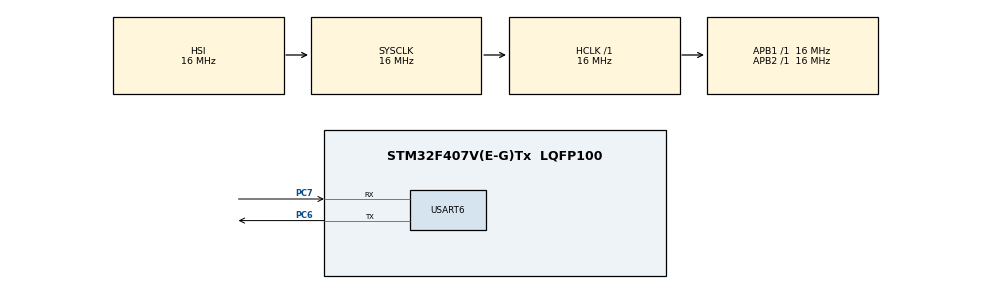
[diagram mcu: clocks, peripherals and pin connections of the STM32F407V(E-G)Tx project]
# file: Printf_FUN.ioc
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Mcu.Family=STM32F4
Mcu.Name=STM32F407V(E-G)Tx
Mcu.Package=LQFP100
NVIC.PriorityGroup=NVIC_PRIORITYGROUP_4
PA13.Mode=Serial_Wire
PA13.Signal=SYS_JTMS-SWDIO
PA14.Mode=Serial_Wire
PA14.Signal=SYS_JTCK-SWCLK
PC6.Mode=Asynchronous
PC6.Signal=USART6_TX
PC7.Mode=Asynchronous
PC7.Signal=USART6_RX
PH0-OSC_IN.Mode=HSE-External-Oscillator
PH0-OSC_IN.Signal=RCC_OSC_IN
PH1-OSC_OUT.Mode=HSE-External-Oscillator
PH1-OSC_OUT.Signal=RCC_OSC_OUT
ProjectManager.HeapSize=0x200
ProjectManager.StackSize=0x400
ProjectManager.TargetToolchain=STM32CubeIDE
RCC.AHBFreq_Value=16000000
RCC.APB1Freq_Value=16000000
RCC.APB2Freq_Value=16000000
RCC.CortexFreq_Value=16000000
RCC.HSE_VALUE=25000000
RCC.HSI_VALUE=16000000
RCC.LSE_VALUE=32768
RCC.SYSCLKFreq_VALUE=16000000
RCC.VCOOutputFreq_Value=192000000
USART6.VirtualMode=VM_ASYNC
board=custom

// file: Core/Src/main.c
/* USER CODE BEGIN Header */
/**
  ******************************************************************************
  * @file           : main.c
  * @brief          : Main program body
  ******************************************************************************
  * @attention
  *
  * Copyright (c) 2023 STMicroelectronics.
  * All rights reserved.
  *
  * This software is licensed under terms that can be found in the LICENSE file
  * in the root directory of this software component.
  * If no LICENSE file comes with this software, it is provided AS-IS.
  *
  ******************************************************************************
  */
/* USER CODE END Header */
#include "main.h"

/* USER CODE BEGIN Includes */
#include<stdio.h>

/* USER CODE END Includes */

UART_HandleTypeDef huart6;

void SystemClock_Config(void);
static void MX_GPIO_Init(void);
static void MX_USART6_UART_Init(void);
/* USER CODE BEGIN PFP */

#define PUTCHAR_PROTOTYPE int __io_putchar(int ch)

/* USER CODE END PFP */

int main(void)
{

  /* MCU Configuration--------------------------------------------------------*/

  /* Reset of all peripherals, Initializes the Flash interface and the Systick. */
  HAL_Init();

  /* Configure the system clock */
  SystemClock_Config();

  /* Initialize all configured peripherals */
  MX_GPIO_Init();
  MX_USART6_UART_Init();
  /* USER CODE BEGIN 2 */
  printf("Hello\n");
  /* USER CODE END 2 */

  /* Infinite loop */
  /* USER CODE BEGIN WHILE */
  while (1)
  {
	  printf("Hello\n");
	  HAL_Delay(1000);
    /* USER CODE END WHILE */

  }
}

void SystemClock_Config(void)
{
  RCC_OscInitTypeDef RCC_OscInitStruct = {0};
  RCC_ClkInitTypeDef RCC_ClkInitStruct = {0};

  /** Configure the main internal regulator output voltage
  */
  __HAL_RCC_PWR_CLK_ENABLE();
  __HAL_PWR_VOLTAGESCALING_CONFIG(PWR_REGULATOR_VOLTAGE_SCALE1);

  /** Initializes the RCC Oscillators according to the specified parameters
  * in the RCC_OscInitTypeDef structure.
  */
  RCC_OscInitStruct.OscillatorType = RCC_OSCILLATORTYPE_HSI;
  RCC_OscInitStruct.HSIState = RCC_HSI_ON;
  RCC_OscInitStruct.HSICalibrationValue = RCC_HSICALIBRATION_DEFAULT;
  RCC_OscInitStruct.PLL.PLLState = RCC_PLL_NONE;
  if (HAL_RCC_OscConfig(&RCC_OscInitStruct) != HAL_OK)
  {
    Error_Handler();
  }

  /** Initializes the CPU, AHB and APB buses clocks
  */
  RCC_ClkInitStruct.ClockType = RCC_CLOCKTYPE_HCLK|RCC_CLOCKTYPE_SYSCLK
                              |RCC_CLOCKTYPE_PCLK1|RCC_CLOCKTYPE_PCLK2;
  RCC_ClkInitStruct.SYSCLKSource = RCC_SYSCLKSOURCE_HSI;
  RCC_ClkInitStruct.AHBCLKDivider = RCC_SYSCLK_DIV1;
  RCC_ClkInitStruct.APB1CLKDivider = RCC_HCLK_DIV1;
  RCC_ClkInitStruct.APB2CLKDivider = RCC_HCLK_DIV1;

  if (HAL_RCC_ClockConfig(&RCC_ClkInitStruct, FLASH_LATENCY_0) != HAL_OK)
  {
    Error_Handler();
  }
}

static void MX_USART6_UART_Init(void)
{

  huart6.Instance = USART6;
  huart6.Init.BaudRate = 115200;
  huart6.Init.WordLength = UART_WORDLENGTH_8B;
  huart6.Init.StopBits = UART_STOPBITS_1;
  huart6.Init.Parity = UART_PARITY_NONE;
  huart6.Init.Mode = UART_MODE_TX_RX;
  huart6.Init.HwFlowCtl = UART_HWCONTROL_NONE;
  huart6.Init.OverSampling = UART_OVERSAMPLING_16;
  if (HAL_UART_Init(&huart6) != HAL_OK)
  {
    Error_Handler();
  }

}

static void MX_GPIO_Init(void)
{

  /* GPIO Ports Clock Enable */
  __HAL_RCC_GPIOH_CLK_ENABLE();
  __HAL_RCC_GPIOC_CLK_ENABLE();
  __HAL_RCC_GPIOA_CLK_ENABLE();

}

/* USER CODE BEGIN 4 */

#ifdef __GNUC__
  /* With GCC/RAISONANCE, small printf (option LD Linker->Libraries->Small printf
     set to 'Yes') calls __io_putchar() */
  #define PUTCHAR_PROTOTYPE int __io_putchar(int ch)
#else
  #define PUTCHAR_PROTOTYPE int fputc(int ch, FILE *f)
#endif /* __GNUC__ */
/**
  * @brief  Retargets the C library printf function to the USART.
  * @param  None
  * @retval None
  */
PUTCHAR_PROTOTYPE
{
  /* Place your implementation of fputc here */
  /* e.g. write a character to the EVAL_COM1 and Loop until the end of transmission */
  HAL_UART_Transmit(&huart6, (uint8_t *)&ch, 1, 0xFFFF);  //make changes in the &huart 1,2,3,... accordingly
  return ch;
}

/* USER CODE END 4 */

void Error_Handler(void)
{
  __disable_irq();
  while (1)
  {
  }
}
